AUTOSAR XML (schema 00044)
package /E40_Platform_System_SystemPackage/Components
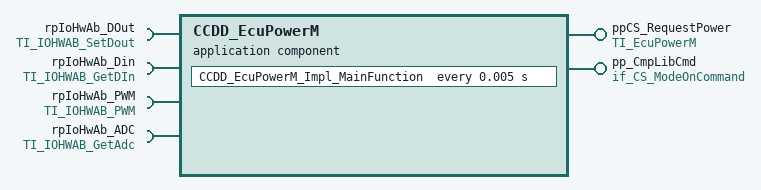
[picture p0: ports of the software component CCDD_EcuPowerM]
  application sw component type CCDD_EcuPowerM
    provide port ppCS_RequestPower: provided-interface=TI_EcuPowerM
      provided-com-specs:
        operation=EcuPowerM_GetDeviceStatus, queue-length=1
        operation=EcuPowerM_RequestPower, queue-length=1
    4 x require port:
      rpIoHwAb_DOut: required-com-specs=[SetOutputGroup, SetOutputPin], required-interface=TI_IOHWAB_SetDout
      rpIoHwAb_Din: required-com-specs=[GetAsyncRawInput, GetInputGroup, GetProcessedInput, GetSyncRawInput], required-interface=TI_IOHWAB_GetDIn
      rpIoHwAb_PWM: required-com-specs=[PwmSetDuty, PwmSetDutyAndPeriod, PwmSetIdeal], required-interface=TI_IOHWAB_PWM
      rpIoHwAb_ADC: required-com-specs=[GetAsyncRawAdc, GetProcessedAdc, GetSyncRawAdc], required-interface=TI_IOHWAB_GetAdc
    provide port pp_CmpLibCmd: server-com-spec{operation=Impl_OnCommand, queue-length=1}, provided-interface=if_CS_ModeOnCommand
    behavior IB_CCDD_EcuPowerM
      operation invoked event OIE_ppCS_RequestPower_EcuPowerM_GetDeviceStatusTrigByEcuPowerM_GetDeviceStatus: start-on-event=EcuPowerM_GetDeviceStatus, operation=ppCS_RequestPower.EcuPowerM_GetDeviceStatus
      operation invoked event OIE_ppCS_RequestPower_EcuPowerM_RequestPowerTrigByEcuPowerM_RequestPower: start-on-event=EcuPowerM_RequestPower, operation=ppCS_RequestPower.EcuPowerM_RequestPower
      timing event TECCDD_EcuPowerM_Impl_MainFunction: start-on-event=CCDD_EcuPowerM_Impl_MainFunction, period=0.005
      operation invoked event OIE_pp_CmpLibCmd_CCDD_EcuPowerM_Impl_OnCommandTrigByImpl_OnCommand: start-on-event=CCDD_EcuPowerM_Impl_OnCommand, operation=pp_CmpLibCmd.Impl_OnCommand
      port-api-options:
        enable-take-address=false, indirect-api=false, port=ppCS_RequestPower
        enable-take-address=false, indirect-api=false, port=rpIoHwAb_DOut
        enable-take-address=false, indirect-api=false, port=rpIoHwAb_Din
        enable-take-address=false, indirect-api=false, port=rpIoHwAb_PWM
        enable-take-address=false, indirect-api=false, port=rpIoHwAb_ADC
        enable-take-address=false, indirect-api=false, port=pp_CmpLibCmd
      4 x runnable, all with can-be-invoked-concurrently=true:
        EcuPowerM_GetDeviceStatus
          12 x sync call:
            OA_rpIoHwAb_DOut_SetOutputGroup: operation=rpIoHwAb_DOut.SetOutputGroup
            OA_rpIoHwAb_DOut_SetOutputPin: operation=rpIoHwAb_DOut.SetOutputPin
            OA_rpIoHwAb_Din_GetAsyncRawInput: operation=rpIoHwAb_Din.GetAsyncRawInput
            OA_rpIoHwAb_Din_GetProcessedInput: operation=rpIoHwAb_Din.GetProcessedInput
            OA_rpIoHwAb_Din_GetSyncRawInput: operation=rpIoHwAb_Din.GetSyncRawInput
            OA_rpIoHwAb_Din_GetInputGroup: operation=rpIoHwAb_Din.GetInputGroup
            OA_rpIoHwAb_PWM_PwmSetDuty: operation=rpIoHwAb_PWM.PwmSetDuty
            OA_rpIoHwAb_PWM_PwmSetDutyAndPeriod: operation=rpIoHwAb_PWM.PwmSetDutyAndPeriod
            OA_rpIoHwAb_PWM_PwmSetIdeal: operation=rpIoHwAb_PWM.PwmSetIdeal
            OA_rpIoHwAb_ADC_GetAsyncRawAdc: operation=rpIoHwAb_ADC.GetAsyncRawAdc
            OA_rpIoHwAb_ADC_GetSyncRawAdc: operation=rpIoHwAb_ADC.GetSyncRawAdc
            OA_rpIoHwAb_ADC_GetProcessedAdc: operation=rpIoHwAb_ADC.GetProcessedAdc
        EcuPowerM_RequestPower
          12 x sync call:
            OA_rpIoHwAb_DOut_SetOutputGroup: operation=rpIoHwAb_DOut.SetOutputGroup
            OA_rpIoHwAb_DOut_SetOutputPin: operation=rpIoHwAb_DOut.SetOutputPin
            OA_rpIoHwAb_Din_GetAsyncRawInput: operation=rpIoHwAb_Din.GetAsyncRawInput
            OA_rpIoHwAb_Din_GetProcessedInput: operation=rpIoHwAb_Din.GetProcessedInput
            OA_rpIoHwAb_Din_GetSyncRawInput: operation=rpIoHwAb_Din.GetSyncRawInput
            OA_rpIoHwAb_Din_GetInputGroup: operation=rpIoHwAb_Din.GetInputGroup
            OA_rpIoHwAb_PWM_PwmSetDuty: operation=rpIoHwAb_PWM.PwmSetDuty
            OA_rpIoHwAb_PWM_PwmSetDutyAndPeriod: operation=rpIoHwAb_PWM.PwmSetDutyAndPeriod
            OA_rpIoHwAb_PWM_PwmSetIdeal: operation=rpIoHwAb_PWM.PwmSetIdeal
            OA_rpIoHwAb_ADC_GetAsyncRawAdc: operation=rpIoHwAb_ADC.GetAsyncRawAdc
            OA_rpIoHwAb_ADC_GetSyncRawAdc: operation=rpIoHwAb_ADC.GetSyncRawAdc
            OA_rpIoHwAb_ADC_GetProcessedAdc: operation=rpIoHwAb_ADC.GetProcessedAdc
        CCDD_EcuPowerM_Impl_MainFunction
          12 x sync call:
            OA_rpIoHwAb_DOut_SetOutputGroup: operation=rpIoHwAb_DOut.SetOutputGroup
            OA_rpIoHwAb_DOut_SetOutputPin: operation=rpIoHwAb_DOut.SetOutputPin
            OA_rpIoHwAb_Din_GetAsyncRawInput: operation=rpIoHwAb_Din.GetAsyncRawInput
            OA_rpIoHwAb_Din_GetProcessedInput: operation=rpIoHwAb_Din.GetProcessedInput
            OA_rpIoHwAb_Din_GetSyncRawInput: operation=rpIoHwAb_Din.GetSyncRawInput
            OA_rpIoHwAb_Din_GetInputGroup: operation=rpIoHwAb_Din.GetInputGroup
            OA_rpIoHwAb_PWM_PwmSetDuty: operation=rpIoHwAb_PWM.PwmSetDuty
            OA_rpIoHwAb_PWM_PwmSetDutyAndPeriod: operation=rpIoHwAb_PWM.PwmSetDutyAndPeriod
            OA_rpIoHwAb_PWM_PwmSetIdeal: operation=rpIoHwAb_PWM.PwmSetIdeal
            OA_rpIoHwAb_ADC_GetAsyncRawAdc: operation=rpIoHwAb_ADC.GetAsyncRawAdc
            OA_rpIoHwAb_ADC_GetSyncRawAdc: operation=rpIoHwAb_ADC.GetSyncRawAdc
            OA_rpIoHwAb_ADC_GetProcessedAdc: operation=rpIoHwAb_ADC.GetProcessedAdc
        CCDD_EcuPowerM_Impl_OnCommand
  swc implementation IMPL_CCDD_EcuPowerM: behavior=IB_CCDD_EcuPowerM
